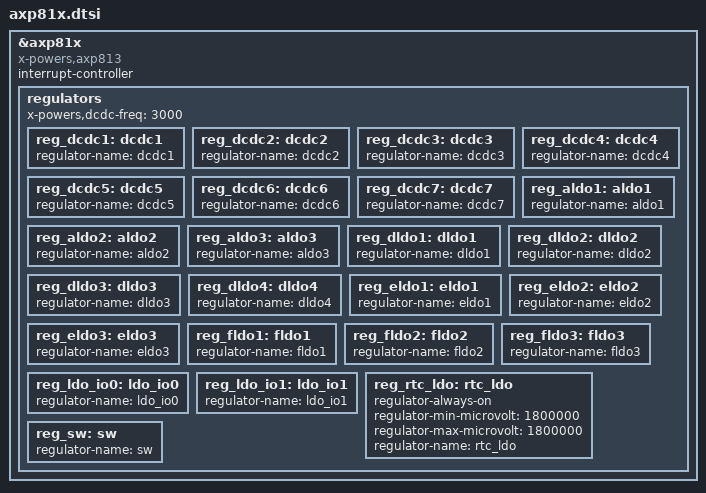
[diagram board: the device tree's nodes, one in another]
/*
 * AXP809 Integrated Power Management Chip
 */

&axp81x {
	compatible = "x-powers,axp813";
	interrupt-controller;
	#interrupt-cells = <1>;

	regulators {
		/* Default work frequency for buck regulators */
		x-powers,dcdc-freq = <3000>;

		reg_dcdc1: dcdc1 {
			regulator-name = "dcdc1";
		};

		reg_dcdc2: dcdc2 {
			regulator-name = "dcdc2";
		};

		reg_dcdc3: dcdc3 {
			regulator-name = "dcdc3";
		};

		reg_dcdc4: dcdc4 {
			regulator-name = "dcdc4";
		};

		reg_dcdc5: dcdc5 {
			regulator-name = "dcdc5";
		};

		reg_dcdc6: dcdc6 {
			regulator-name = "dcdc6";
		};

		reg_dcdc7: dcdc7 {
			regulator-name = "dcdc7";
		};

		reg_aldo1: aldo1 {
			regulator-name = "aldo1";
		};

		reg_aldo2: aldo2 {
			regulator-name = "aldo2";
		};

		reg_aldo3: aldo3 {
			regulator-name = "aldo3";
		};

		reg_dldo1: dldo1 {
			regulator-name = "dldo1";
		};

		reg_dldo2: dldo2 {
			regulator-name = "dldo2";
		};

		reg_dldo3: dldo3 {
			regulator-name = "dldo3";
		};

		reg_dldo4: dldo4 {
			regulator-name = "dldo4";
		};

		reg_eldo1: eldo1 {
			regulator-name = "eldo1";
		};

		reg_eldo2: eldo2 {
			regulator-name = "eldo2";
		};

		reg_eldo3: eldo3 {
			regulator-name = "eldo3";
		};

		reg_fldo1: fldo1 {
			regulator-name = "fldo1";
		};

		reg_fldo2: fldo2 {
			regulator-name = "fldo2";
		};

		reg_fldo3: fldo3 {
			regulator-name = "fldo3";
		};

		reg_ldo_io0: ldo_io0 {
			regulator-name = "ldo_io0";
		};

		reg_ldo_io1: ldo_io1 {
			regulator-name = "ldo_io1";
		};

		reg_rtc_ldo: rtc_ldo {
			/* RTC_LDO is a fixed, always-on regulator */
			regulator-always-on;
			regulator-min-microvolt = <1800000>;
			regulator-max-microvolt = <1800000>;
			regulator-name = "rtc_ldo";
		};

		reg_sw: sw {
			regulator-name = "sw";
		};
	};
};
